# STM32F446MCY6 register map
File version: 1.0
Registers are 32-bit, access not given, reset 0x0 unless marked. A register's access mark holds for its fields unless they carry their own. Offsets are from the block's base; [hi:lo] are bit positions; {n}, {i} and the like mark numbered series; 'fields as' and 'values as' point back to an identical list.

## SYSCFG
Base 0x40013800
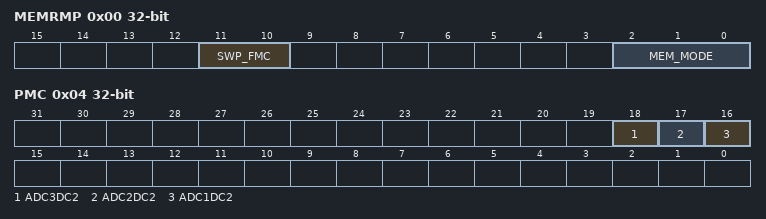
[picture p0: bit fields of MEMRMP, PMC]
0x00 MEMRMP
  [11:10] SWP_FMC, [2:0] MEM_MODE
0x04 PMC
  [18] ADC3DC2, [17] ADC2DC2, [16] ADC1DC2
{0x4+4i} EXTICR{i} (i=1..4)
0x20 CMPCR
0x2C CFGR

## EXTI
Base 0x40013C00
0x00 IMR
0x04 EMR
0x08 RTSR
0x0C FTSR
0x10 SWIER
0x14 PR

## SAI1
Base 0x40015800
Same registers: SAI2 0x40015C00
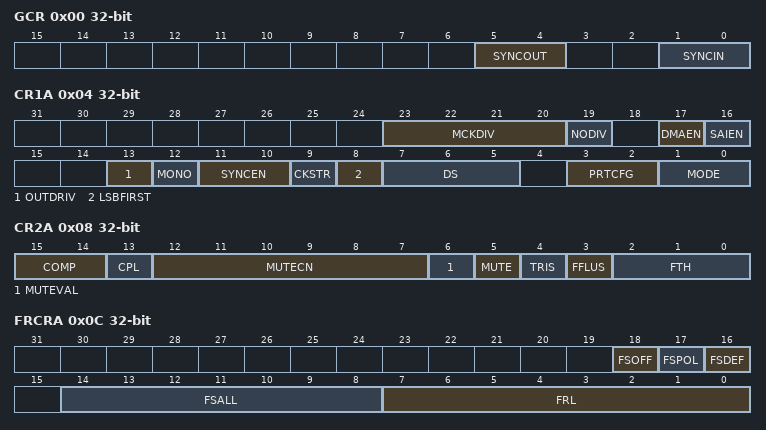
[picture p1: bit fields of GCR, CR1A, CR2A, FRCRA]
0x00 GCR
  [5:4] SYNCOUT, [1:0] SYNCIN
0x04 CR1A
  [23:20] MCKDIV, [19] NODIV, [17] DMAEN, [16] SAIEN, [13] OUTDRIV, [12] MONO, [11:10] SYNCEN, [9] CKSTR, [8] LSBFIRST, [7:5] DS, [3:2] PRTCFG, [1:0] MODE
0x08 CR2A
  [15:14] COMP, [13] CPL, [12:7] MUTECN, [6] MUTEVAL, [5] MUTE, [4] TRIS, [3] FFLUS, [2:0] FTH
0x0C FRCRA
  [18] FSOFF, [17] FSPOL, [16] FSDEF, [14:8] FSALL, [7:0] FRL
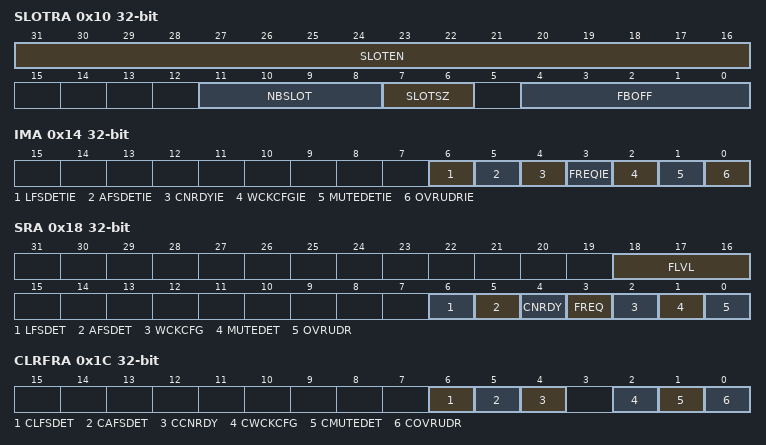
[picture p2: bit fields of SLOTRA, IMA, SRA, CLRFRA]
0x10 SLOTRA
  [31:16] SLOTEN, [11:8] NBSLOT, [7:6] SLOTSZ, [4:0] FBOFF
0x14 IMA
  [6] LFSDETIE, [5] AFSDETIE, [4] CNRDYIE, [3] FREQIE, [2] WCKCFGIE, [1] MUTEDETIE, [0] OVRUDRIE
0x18 SRA
  [18:16] FLVL, [6] LFSDET, [5] AFSDET, [4] CNRDY, [3] FREQ, [2] WCKCFG, [1] MUTEDET, [0] OVRUDR
0x1C CLRFRA
  [6] CLFSDET, [5] CAFSDET, [4] CCNRDY, [2] CWCKCFG, [1] CMUTEDET, [0] COVRUDR
0x20 DRA
  [31:0] DATA
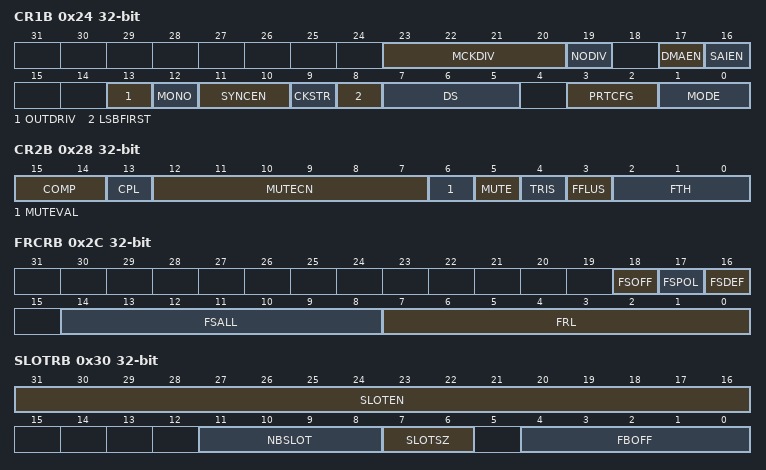
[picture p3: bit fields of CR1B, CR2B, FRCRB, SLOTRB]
0x24 CR1B
  fields as CR1A
0x28 CR2B
  fields as CR2A
0x2C FRCRB
  [18] FSOFF, [17] FSPOL, [16] FSDEF, [14:8] FSALL, [7:0] FRL
0x30 SLOTRB
  [31:16] SLOTEN, [11:8] NBSLOT, [7:6] SLOTSZ, [4:0] FBOFF
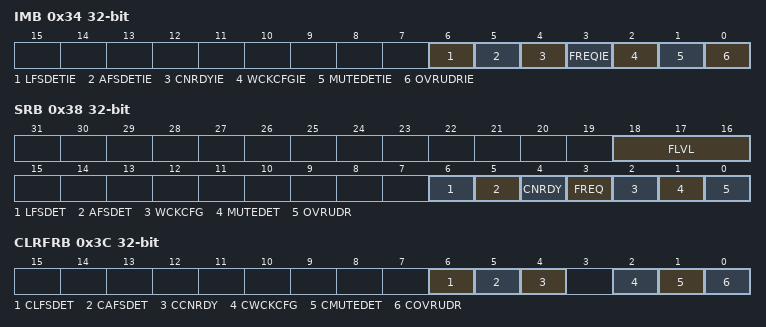
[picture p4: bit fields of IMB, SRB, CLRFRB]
0x34 IMB
  fields as IMA
0x38 SRB
  fields as SRA
0x3C CLRFRB
  fields as CLRFRA
0x40 DRB
  [31:0] DATA

## GPIOA
Base 0x40020000
Same registers: GPIOB 0x40020400, GPIOC 0x40020800, GPIOD 0x40020C00, GPIOE 0x40021000, GPIOF 0x40021400, GPIOG 0x40021800, GPIOH 0x40021C00
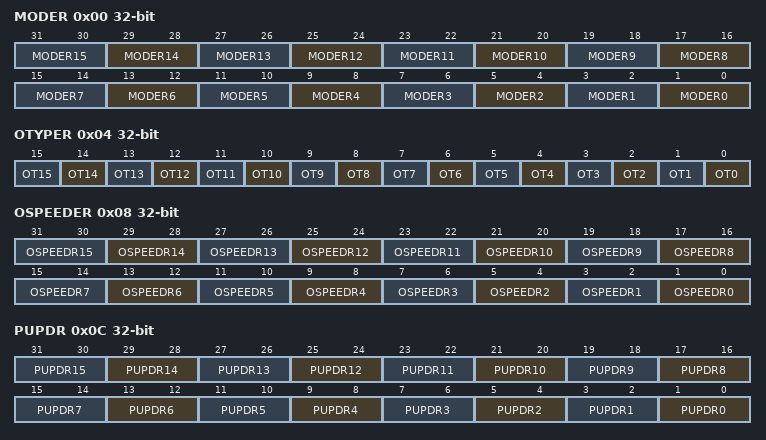
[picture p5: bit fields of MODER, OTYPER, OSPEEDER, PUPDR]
0x00 MODER
  [2n+1:2n] MODER{n} (n=0..15)
0x04 OTYPER
  [n] OT{n} (n=0..15)
0x08 OSPEEDER
  [2n+1:2n] OSPEEDR{n} (n=0..15)
0x0C PUPDR
  [2n+1:2n] PUPDR{n} (n=0..15)
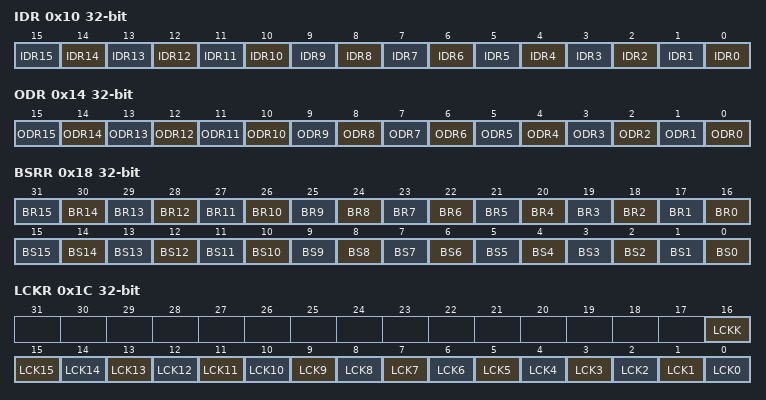
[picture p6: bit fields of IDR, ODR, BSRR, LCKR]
0x10 IDR
  [n] IDR{n} (n=0..15)
0x14 ODR
  [n] ODR{n} (n=0..15)
0x18 BSRR
  [n+16] BR{n} (n=0..15), [n] BS{n} (n=0..15)
0x1C LCKR
  [16] LCKK, [n] LCK{n} (n=0..15)
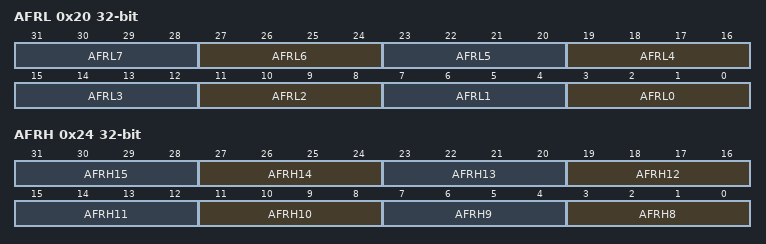
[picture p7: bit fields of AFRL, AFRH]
0x20 AFRL
  [4n+3:4n] AFRL{n} (n=0..7)
0x24 AFRH
  [4n-29:4n-32] AFRH{n} (n=8..15)

## CRC
Base 0x40023000
0x00 DR
  [31:0] DATA
0x04 IDR
  [7:0] DATA
0x08 CR
  [0] RESET

## FLASH
Base 0x40023C00
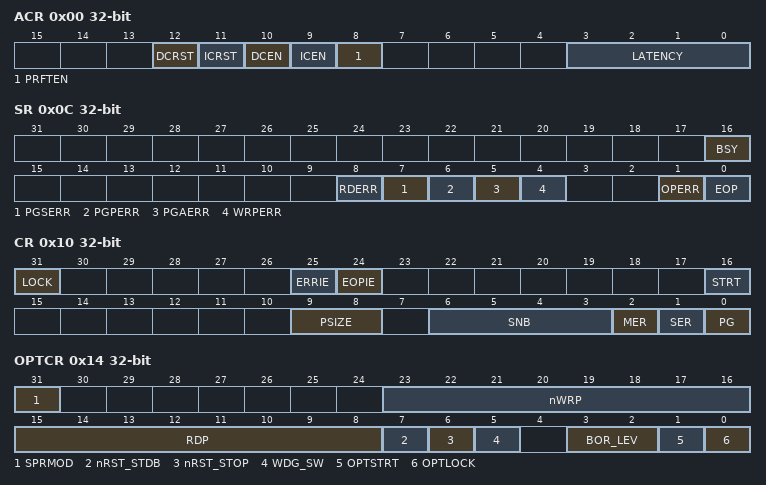
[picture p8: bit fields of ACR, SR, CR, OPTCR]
0x00 ACR
  [12] DCRST, [11] ICRST, [10] DCEN, [9] ICEN, [8] PRFTEN, [3:0] LATENCY
0x04 KEYR
  [31:0] KEY
0x08 OPTKEYR
0x0C SR
  [16] BSY, [8] RDERR, [7] PGSERR, [6] PGPERR, [5] PGAERR, [4] WRPERR, [1] OPERR, [0] EOP
0x10 CR
  [31] LOCK, [25] ERRIE, [24] EOPIE, [16] STRT, [9:8] PSIZE, [6:3] SNB, [2] MER, [1] SER, [0] PG
0x14 OPTCR
  [31] SPRMOD, [23:16] nWRP, [15:8] RDP, [7] nRST_STDB, [6] nRST_STOP, [5] WDG_SW, [3:2] BOR_LEV, [1] OPTSTRT, [0] OPTLOCK

## DMA1
Base 0x40026000
Same registers: DMA2 0x40026400
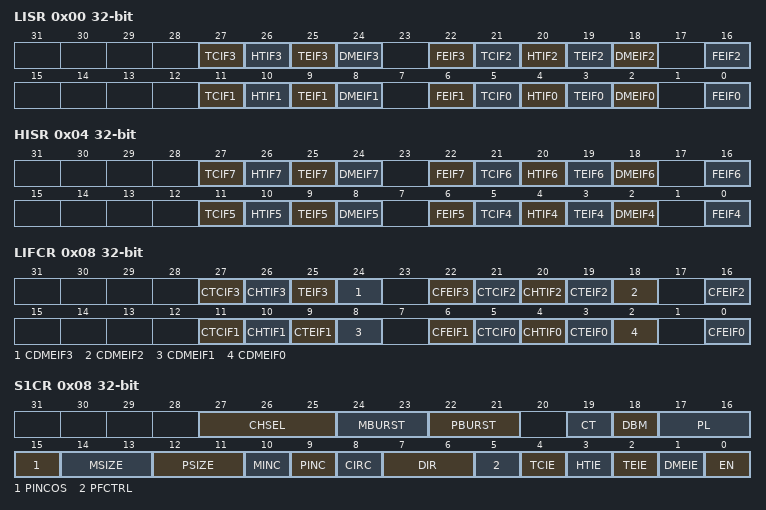
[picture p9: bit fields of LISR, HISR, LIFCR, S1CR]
0x00 LISR
  [27] TCIF3, [26] HTIF3, [25] TEIF3, [24] DMEIF3, [22] FEIF3, [21] TCIF2, [20] HTIF2, [19] TEIF2, [18] DMEIF2, [16] FEIF2, [11] TCIF1, [10] HTIF1, [9] TEIF1, [8] DMEIF1, [6] FEIF1, [5] TCIF0, [4] HTIF0, [3] TEIF0, [2] DMEIF0, [0] FEIF0
0x04 HISR
  [27] TCIF7, [26] HTIF7, [25] TEIF7, [24] DMEIF7, [22] FEIF7, [21] TCIF6, [20] HTIF6, [19] TEIF6, [18] DMEIF6, [16] FEIF6, [11] TCIF5, [10] HTIF5, [9] TEIF5, [8] DMEIF5, [6] FEIF5, [5] TCIF4, [4] HTIF4, [3] TEIF4, [2] DMEIF4, [0] FEIF4
0x08 LIFCR
  [27] CTCIF3, [26] CHTIF3, [25] TEIF3, [24] CDMEIF3, [22] CFEIF3, [21] CTCIF2, [20] CHTIF2, [19] CTEIF2, [18] CDMEIF2, [16] CFEIF2, [11] CTCIF1, [10] CHTIF1, [9] CTEIF1, [8] CDMEIF1, [6] CFEIF1, [5] CTCIF0, [4] CHTIF0, [3] CTEIF0, [2] CDMEIF0, [0] CFEIF0
0x08 S1CR
  [27:25] CHSEL, [24:23] MBURST, [22:21] PBURST, [19] CT, [18] DBM, [17:16] PL, [15] PINCOS, [14:13] MSIZE, [12:11] PSIZE, [10] MINC, [9] PINC, [8] CIRC, [7:6] DIR, [5] PFCTRL, [4] TCIE, [3] HTIE, [2] TEIE, [1] DMEIE, [0] EN
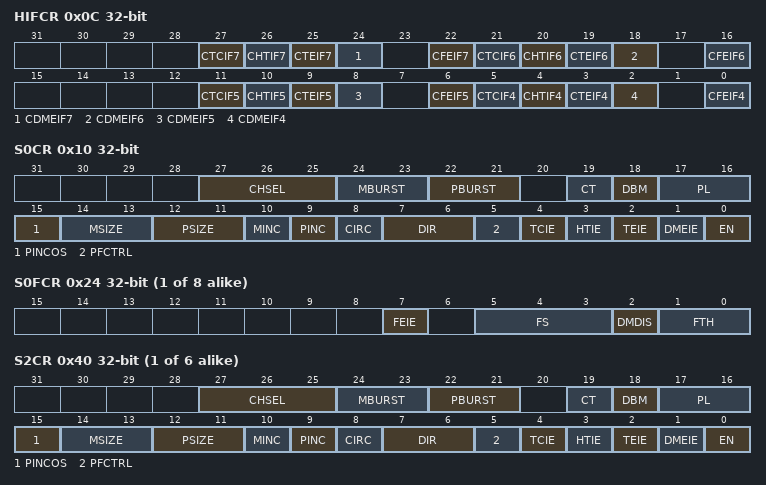
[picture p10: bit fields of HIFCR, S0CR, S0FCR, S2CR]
0x0C HIFCR
  [27] CTCIF7, [26] CHTIF7, [25] CTEIF7, [24] CDMEIF7, [22] CFEIF7, [21] CTCIF6, [20] CHTIF6, [19] CTEIF6, [18] CDMEIF6, [16] CFEIF6, [11] CTCIF5, [10] CHTIF5, [9] CTEIF5, [8] CDMEIF5, [6] CFEIF5, [5] CTCIF4, [4] CHTIF4, [3] CTEIF4, [2] CDMEIF4, [0] CFEIF4
0x10 S0CR
  fields as S1CR
{0x14+0x18*i} S{i}NDTR (i=0..7)
  [15:0] NDT
{0x18+0x18*i} S{i}PAR (i=0..7)
  [31:0] PA
{0x1C+0x18*i} S{i}M0AR (i=0..7)
  [31:0] M0A
{0x20+0x18*i} S{i}M1AR (i=0..7)
  [31:0] M1A
{0x24+0x18*i} S{i}FCR (i=0..7)
  [7] FEIE, [5:3] FS, [2] DMDIS, [1:0] FTH
{0x10+0x18*i} S{i}CR (i=2..7)
  fields as S1CR

## DCMI
Base 0x50050000
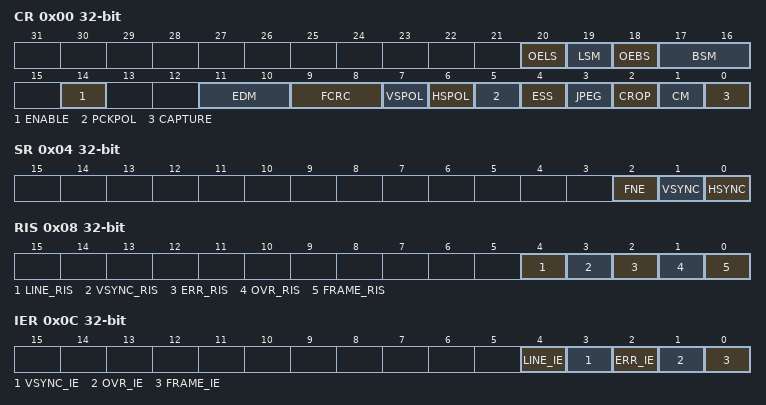
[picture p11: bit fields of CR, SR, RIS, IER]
0x00 CR
  [20] OELS, [19] LSM, [18] OEBS, [17:16] BSM, [14] ENABLE, [11:10] EDM, [9:8] FCRC, [7] VSPOL, [6] HSPOL, [5] PCKPOL, [4] ESS, [3] JPEG, [2] CROP, [1] CM, [0] CAPTURE
0x04 SR
  [2] FNE, [1] VSYNC, [0] HSYNC
0x08 RIS
  [4] LINE_RIS, [3] VSYNC_RIS, [2] ERR_RIS, [1] OVR_RIS, [0] FRAME_RIS
0x0C IER
  [4] LINE_IE, [3] VSYNC_IE, [2] ERR_IE, [1] OVR_IE, [0] FRAME_IE
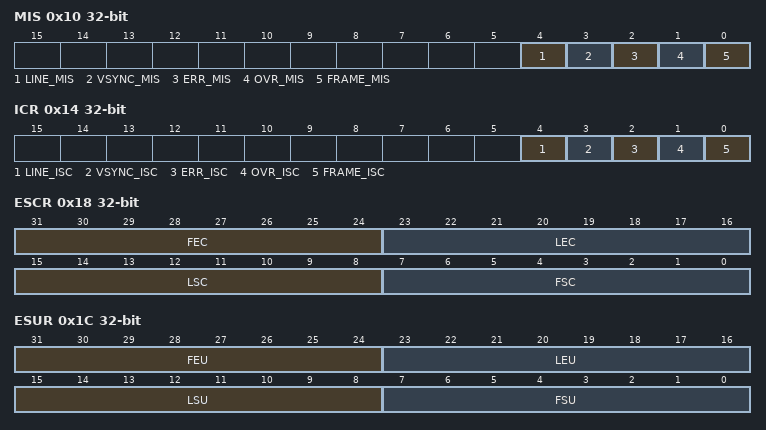
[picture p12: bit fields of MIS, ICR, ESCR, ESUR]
0x10 MIS
  [4] LINE_MIS, [3] VSYNC_MIS, [2] ERR_MIS, [1] OVR_MIS, [0] FRAME_MIS
0x14 ICR
  [4] LINE_ISC, [3] VSYNC_ISC, [2] ERR_ISC, [1] OVR_ISC, [0] FRAME_ISC
0x18 ESCR
  [31:24] FEC, [23:16] LEC, [15:8] LSC, [7:0] FSC
0x1C ESUR
  [31:24] FEU, [23:16] LEU, [15:8] LSU, [7:0] FSU
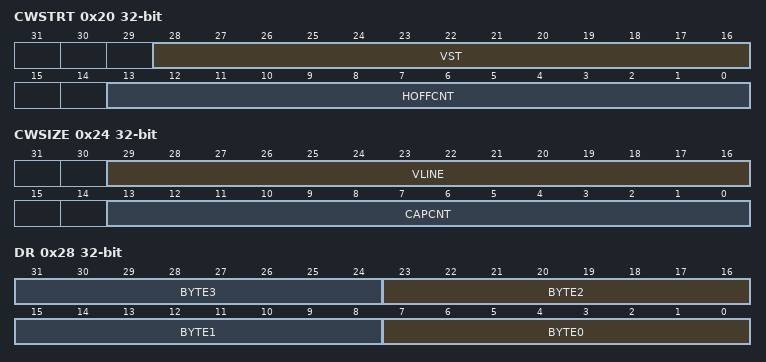
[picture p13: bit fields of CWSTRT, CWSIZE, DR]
0x20 CWSTRT
  [28:16] VST, [13:0] HOFFCNT
0x24 CWSIZE
  [29:16] VLINE, [13:0] CAPCNT
0x28 DR
  [8n+7:8n] BYTE{n} (n=0..3)

## FMC
Base 0xA0000000
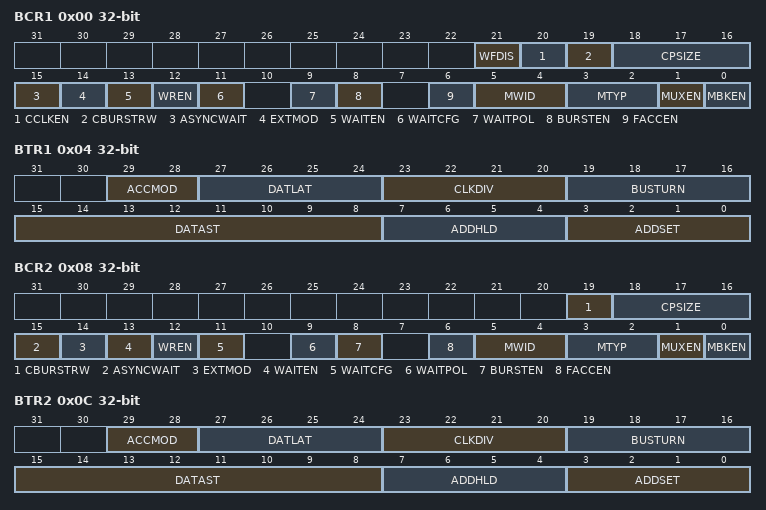
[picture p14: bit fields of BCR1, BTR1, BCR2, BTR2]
0x00 BCR1
  [21] WFDIS, [20] CCLKEN, [19] CBURSTRW, [18:16] CPSIZE, [15] ASYNCWAIT, [14] EXTMOD, [13] WAITEN, [12] WREN, [11] WAITCFG, [9] WAITPOL, [8] BURSTEN, [6] FACCEN, [5:4] MWID, [3:2] MTYP, [1] MUXEN, [0] MBKEN
0x04 BTR1
  [29:28] ACCMOD, [27:24] DATLAT, [23:20] CLKDIV, [19:16] BUSTURN, [15:8] DATAST, [7:4] ADDHLD, [3:0] ADDSET
0x08 BCR2
  [19] CBURSTRW, [18:16] CPSIZE, [15] ASYNCWAIT, [14] EXTMOD, [13] WAITEN, [12] WREN, [11] WAITCFG, [9] WAITPOL, [8] BURSTEN, [6] FACCEN, [5:4] MWID, [3:2] MTYP, [1] MUXEN, [0] MBKEN
0x0C BTR2
  fields as BTR1
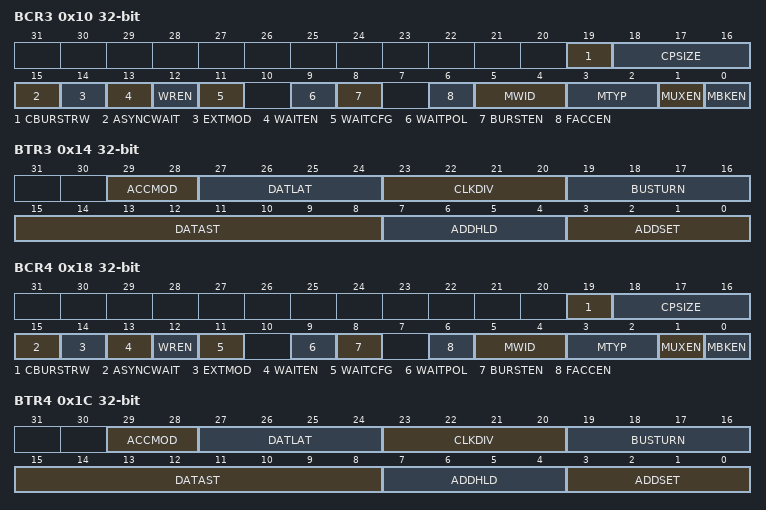
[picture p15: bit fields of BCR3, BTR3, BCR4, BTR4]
0x10 BCR3
  fields as BCR2
0x14 BTR3
  fields as BTR1
0x18 BCR4
  fields as BCR2
0x1C BTR4
  fields as BTR1
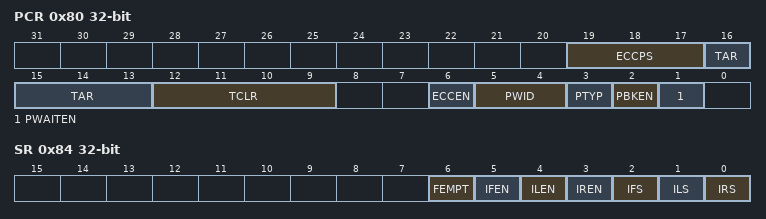
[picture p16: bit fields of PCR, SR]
0x80 PCR
  [19:17] ECCPS, [16:13] TAR, [12:9] TCLR, [6] ECCEN, [5:4] PWID, [3] PTYP, [2] PBKEN, [1] PWAITEN
0x84 SR
  [6] FEMPT, [5] IFEN, [4] ILEN, [3] IREN, [2] IFS, [1] ILS, [0] IRS
0x88 PMEM
  [31:24] MEMHIZx, [23:16] MEMHOLDx, [15:8] MEMWAITx, [7:0] MEMSETx
0x8C PATT
  [31:24] ATTHIZ, [23:16] ATTHOLD, [15:8] ATTWAIT, [7:0] ATTSET
0x94 ECCR
  [31:0] ECCx
{0xFC+8i} BWTR{i} (i=1..4)
  [29:28] ACCMOD, [19:16] BUSTURN, [15:8] DATAST, [7:4] ADDHLD, [3:0] ADDSET
0x140 SDCR1
  [14:13] RPIPE, [12] RBURST, [11:10] SDCLK, [9] WP, [8:7] CAS, [6] NB, [5:4] MWID, [3:2] NR, [1:0] NC
0x144 SDCR2
  [12] RBURST, [11:10] SDCLK, [9] WP, [8:7] CAS, [6] NB, [5:4] MWID, [3:2] NR, [1:0] NC
0x148 SDTR1
  [27:24] TRCD, [23:20] TRP, [19:16] TWR, [15:12] TRC, [11:8] TRAS, [7:4] TXSR, [3:0] TMRD
0x14C SDTR2
  fields as SDTR1
0x150 SDCMR
  [21:9] MRD, [8:5] NRFS, [4] CTB1, [3] CTB2, [2:0] MODE
0x154 SDRTR
  [14] REIE, [13:1] COUNT, [0] CRE
0x158 SDSR
  [5] BUSY, [4:3] MODES2, [2:1] MODES1

## QUADSPI
Base 0xA0001000
0x00 CR
  [31:24] PRESCALER, [23] PMM, [22] APMS, [20] TOIE, [19] SMIE, [18] FTIE, [17] TCIE, [16] TEIE, [12:8] FTHRES, [7] FSEL, [6] DFM, [4] SSHIFT, [3] TCEN, [2] DMAEN, [1] ABORT, [0] EN
0x04 DCR
  [20:16] FSIZE, [10:8] CSHT, [0] CKMODE
0x08 SR
  [13:8] FLEVEL, [5] BUS, [4] TOF, [3] SMF, [2] FTF, [1] TCF, [0] TEF
0x0C FCR
  [4] CTOF, [3] CSMF, [1] CTCF, [0] CTEF
0x10 DLR
  [31:0] DL
0x14 CCR
  [31] DDRM, [30] DHHC, [28] SIOO, [27:26] FMODE, [25:24] DMODE, [22:18] DCYC, [17:16] ABSIZE, [15:14] ABMODE, [13:12] ADSIZE, [11:10] ADMODE, [9:8] IMODE, [7:0] INSTRUCTION
0x18 AR
  [31:0] ADDRESS
0x1C ABR
  [31:0] ALTERNATE
0x20 DR
  [31:0] DATA
0x24 PSMKR
  [31:0] MASK
0x28 PSMAR
  [31:0] MATCH
0x2C PIR
  [15:0] INTERVAL
0x30 LPTR
  [15:0] TIMEOUT
